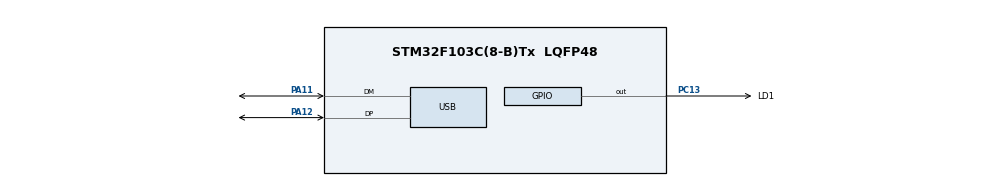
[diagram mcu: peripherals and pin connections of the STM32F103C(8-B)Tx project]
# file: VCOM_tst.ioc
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Mcu.Family=STM32F1
RCC.PLLSourceVirtual=RCC_PLLSOURCE_HSE
USB_DEVICE.CLASS_NAME_FS=CDC
PD1-OSC_OUT.Mode=HSE-External-Oscillator
USB_DEVICE.VirtualModeFS=Cdc_FS
PC13-TAMPER-RTC.Signal=GPIO_Output
RCC.USBPrescaler=RCC_USBCLKSOURCE_PLL_DIV1_5
PA11.Mode=Device
PD0-OSC_IN.Signal=RCC_OSC_IN
RCC.APB1CLKDivider=RCC_HCLK_DIV2
RCC.SYSCLKSource=RCC_SYSCLKSOURCE_PLLCLK
ProjectManager.StackSize=0x400
PD1-OSC_OUT.Signal=RCC_OSC_OUT
PA13.Signal=SYS_JTMS-SWDIO
PA12.Signal=USB_DP
ProjectManager.TargetToolchain=STM32CubeIDE
RCC.HCLKFreq_Value=72000000
VP_USB_DEVICE_VS_USB_DEVICE_CDC_FS.Mode=CDC_FS
RCC.APB2TimFreq_Value=72000000
RCC.USBFreq_Value=48000000
RCC.AHBFreq_Value=72000000
PD0-OSC_IN.Mode=HSE-External-Oscillator
board=custom
RCC.PLLMUL=RCC_PLL_MUL9
PC13-TAMPER-RTC.GPIO_Label=LD1
RCC.APB2Freq_Value=72000000
PC13-TAMPER-RTC.PinState=GPIO_PIN_SET
PA14.Mode=Serial_Wire
NVIC.USB_LP_CAN1_RX0_IRQn=true\:0\:0\:false\:false\:true\:false\:true
PA13.Mode=Serial_Wire
Mcu.Name=STM32F103C(8-B)Tx
RCC.SYSCLKFreq_VALUE=72000000
Mcu.Package=LQFP48
PA12.Mode=Device
PA11.Signal=USB_DM
PA14.Signal=SYS_JTCK-SWCLK
ProjectManager.HeapSize=0x200
NVIC.PriorityGroup=NVIC_PRIORITYGROUP_4
RCC.APB1TimFreq_Value=72000000
RCC.APB1Freq_Value=36000000
USB_DEVICE.VirtualMode=Cdc

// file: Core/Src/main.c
/* USER CODE BEGIN Header */
/**
  ******************************************************************************
  * @file           : main.c
  * @brief          : Main program body
  ******************************************************************************
  * @attention
  *
  * <h2><center>&copy; Copyright (c) 2021 STMicroelectronics.
  * All rights reserved.</center></h2>
  *
  * This software component is licensed by ST under BSD 3-Clause license,
  * the "License"; You may not use this file except in compliance with the
  * License. You may obtain a copy of the License at:
  *                        opensource.org/licenses/BSD-3-Clause
  *
  ******************************************************************************
  */
/* USER CODE END Header */
#include "main.h"
#include "usb_device.h"
#include "gpio.h"

/* USER CODE BEGIN Includes */
#include "usbd_cdc_if.h"
/* USER CODE END Includes */

void SystemClock_Config(void);

/* USER CODE BEGIN 0 */
uint8_t data1[50]={"this is an example message\n"};
/* USER CODE END 0 */

int main(void)
{

  /* MCU Configuration--------------------------------------------------------*/

  /* Reset of all peripherals, Initializes the Flash interface and the Systick. */
  HAL_Init();

  /* Configure the system clock */
  SystemClock_Config();

  /* Initialize all configured peripherals */
  MX_GPIO_Init();
  MX_USB_DEVICE_Init();

  /* Infinite loop */
  while (1)
  {

    /* USER CODE BEGIN 3 */
	   CDC_Transmit_FS(data1,29);
	   LL_GPIO_TogglePin(LD1_GPIO_Port, LD1_Pin);
	   LL_mDelay(1000);
  }
  /* USER CODE END 3 */
}

void SystemClock_Config(void)
{
  LL_FLASH_SetLatency(LL_FLASH_LATENCY_2);
  while(LL_FLASH_GetLatency()!= LL_FLASH_LATENCY_2)
  {
  }
  LL_RCC_HSE_Enable();

   /* Wait till HSE is ready */
  while(LL_RCC_HSE_IsReady() != 1)
  {

  }
  LL_RCC_PLL_ConfigDomain_SYS(LL_RCC_PLLSOURCE_HSE_DIV_1, LL_RCC_PLL_MUL_9);
  LL_RCC_PLL_Enable();

   /* Wait till PLL is ready */
  while(LL_RCC_PLL_IsReady() != 1)
  {

  }
  LL_RCC_SetAHBPrescaler(LL_RCC_SYSCLK_DIV_1);
  LL_RCC_SetAPB1Prescaler(LL_RCC_APB1_DIV_2);
  LL_RCC_SetAPB2Prescaler(LL_RCC_APB2_DIV_1);
  LL_RCC_SetSysClkSource(LL_RCC_SYS_CLKSOURCE_PLL);

   /* Wait till System clock is ready */
  while(LL_RCC_GetSysClkSource() != LL_RCC_SYS_CLKSOURCE_STATUS_PLL)
  {

  }
  LL_SetSystemCoreClock(72000000);

   /* Update the time base */
  if (HAL_InitTick (TICK_INT_PRIORITY) != HAL_OK)
  {
    Error_Handler();
  }
  LL_RCC_SetUSBClockSource(LL_RCC_USB_CLKSOURCE_PLL_DIV_1_5);
}

void Error_Handler(void)
{
  __disable_irq();
  while (1)
  {
  }
}

/************************ (C) COPYRIGHT STMicroelectronics *****END OF FILE****/
